# GD32H71x_72x register map
File version: 1.0
CPU: CM7 r1p2, little endian, MPU, FPU, 4 interrupt priority bits
Registers are 32-bit, read-write, reset 0x0 unless marked. A register's access mark holds for its fields unless they carry their own. Offsets are from the block's base; [hi:lo] are bit positions; {n}, {i} and the like mark numbered series.

## RCU — Reset and clock unit
Base 0x58024400
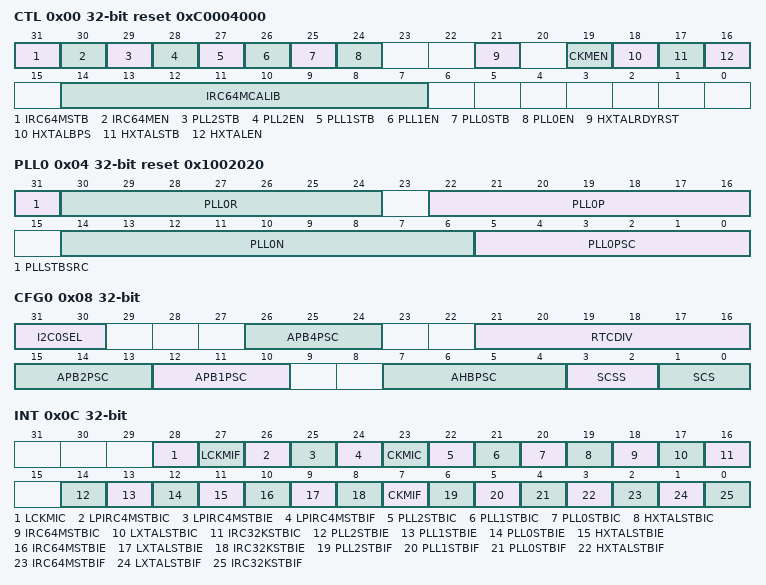
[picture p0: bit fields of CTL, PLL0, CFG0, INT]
0x00 CTL access per field reset 0xC0004000 — Control register
  [31] IRC64MSTB ro — Internal 64MHz RC oscillator stabilization flag
  [30] IRC64MEN rw — Internal 64MHz RC oscillator enable
  [29] PLL2STB ro — PLL2 clock stabilization flag
  [28] PLL2EN rw — PLL2 enable
  [27] PLL1STB ro — PLL1 clock stabilization flag
  [26] PLL1EN rw — PLL1 enable
  [25] PLL0STB ro — PLL0 clock ready flag
  [24] PLL0EN rw — PLL0 enable
  [21] HXTALRDYRST rw — HXTAL ready reset
  [19] CKMEN rw — HXTAL clock monitor enable
  [18] HXTALBPS rw — High-speed crystal oscillator (HXTAL) clock bypass mode enable
  [17] HXTALSTB ro — High-speed crystal oscillator (HXTAL) clock stability flag bit
  [16] HXTALEN rw — High-speed crystal oscillator (HXTAL) enable
  [14:7] IRC64MCALIB ro — Internal 64 MHz RC oscillator calibration value
0x04 PLL0 access per field reset 0x1002020
  [31] PLLSTBSRC wo — PLLs stabilization signal sources.
  [30:24] PLL0R rw — Division factor of the PLL0R output frequency (PLL0 VCO clock as input)
  [22:16] PLL0P rw — PLL0P output frequency division factor (PLL0 VCO clock as input)
  [14:6] PLL0N rw — PLL0 VCO clock multiplication factor
  [5:0] PLL0PSC rw — PLL0 VCO source clock divider
0x08 CFG0 access per field — Clock configuration register 0
  [31:30] I2C0SEL rw — I2C0 clock source selection
  [26:24] APB4PSC rw — APB4 prescaler selection
  [21:16] RTCDIV rw — RTC clock prescaler factor
  [15:13] APB2PSC rw — APB2 prescaler selection
  [12:10] APB1PSC rw — APB1 prescaler selection
  [7:4] AHBPSC rw — AHB / AXI prescaler selection
  [3:2] SCSS ro — System clock selection status
  [1:0] SCS rw — System clock selection
0x0C INT access per field — Clock interrupt register
  [28] LCKMIC wo — LXTAL clock stuck interrupt clear
  [27] LCKMIF ro — LXTAL clock stuck interrupt flag
  [26] LPIRC4MSTBIC wo — LPIRC4M clock stabilization interrupt clear
  [25] LPIRC4MSTBIE rw — LPIRC4M clock stabilization interrupt enable
  [24] LPIRC4MSTBIF ro — LPIRC4M clock stable interrupt flag bit
  [23] CKMIC wo — HXTAL clock stuck interrupt cleared.
  [22] PLL2STBIC wo — PLL2 stabilization interrupt clear
  [21] PLL1STBIC wo — PLL1 stabilization interrupt clear
  [20] PLL0STBIC wo — PLL0 stabilization interrupt clear
  [19] HXTALSTBIC wo — HXTAL stabilization interrupt clear
  [18] IRC64MSTBIC wo — IRC64M stabilization interrupt clear
  [17] LXTALSTBIC wo — LXTAL stabilization interrupt clear
  [16] IRC32KSTBIC wo — IRC32K stabilization interrupt clear
  [14] PLL2STBIE rw — PLL2 stabilization interrupt enable
  [13] PLL1STBIE rw — PLL1 stabilization interrupt enable
  [12] PLL0STBIE rw — PLL0 stabilization interrupt enable
  [11] HXTALSTBIE rw — HXTAL stabilization interrupt enable
  [10] IRC64MSTBIE rw — IRC64M stabilization interrupt enable
  [9] LXTALSTBIE rw — LXTAL stabilization interrupt enable
  [8] IRC32KSTBIE rw — IRC32K stabilization interrupt enable
  [7] CKMIF ro — HXTAL clock stuck interrupt flag bit
  [6] PLL2STBIF ro — PLL2 stabilization interrupt flag
  [5] PLL1STBIF ro — PLL1 stabilization interrupt flag
  [4] PLL0STBIF ro — PLL0 stabilization interrupt flag
  [3] HXTALSTBIF ro — HXTAL stabilization interrupt flag
  [2] IRC64MSTBIF ro — IRC64M stabilization interrupt flag
  [1] LXTALSTBIF ro — LXTAL stabilization interrupt flag
  [0] IRC32KSTBIF ro — IRC32K stabilization interrupt flag
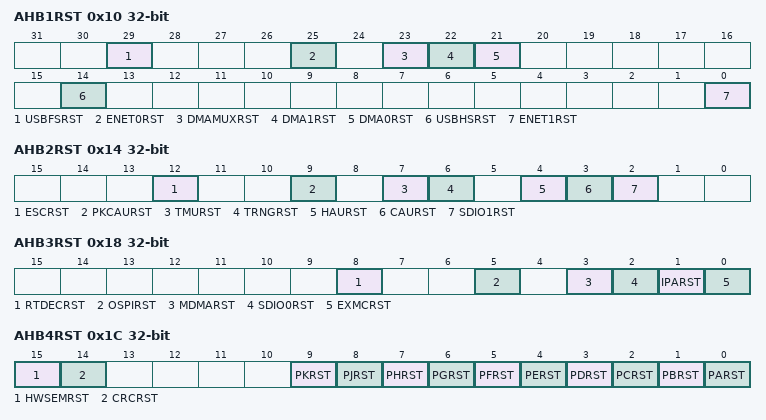
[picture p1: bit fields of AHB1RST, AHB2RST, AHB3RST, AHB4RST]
0x10 AHB1RST — AHB1 reset register
  [29] USBFSRST — USBFS reset
  [25] ENET0RST — Ethernet0 reset
  [23] DMAMUXRST — DMAMUX reset
  [22] DMA1RST — DMA1 reset
  [21] DMA0RST — DMA0 reset
  [14] USBHSRST — USBHS reset
  [0] ENET1RST — Ethernet1 reset
0x14 AHB2RST — AHB2 reset register
  [12] ESCRST — ESC reset
  [9] PKCAURST — PKCAU reset
  [7] TMURST — TMU reset
  [6] TRNGRST — TRNG reset
  [4] HAURST — HAU reset
  [3] CAURST — CAU reset
  [2] SDIO1RST — SDIO1 reset
0x18 AHB3RST — AHB3 reset register
  [8] RTDECRST — RTDEC reset
  [5] OSPIRST — OSPI reset
  [3] MDMARST — MDMA reset
  [2] SDIO0RST — SDIO0 reset
  [1] IPARST — IPA reset
  [0] EXMCRST — EXMC reset
0x1C AHB4RST — AHB4 reset register
  [15] HWSEMRST — HWSEM reset
  [14] CRCRST — CRC reset
  [9] PKRST — GPIO port K reset
  [8] PJRST — GPIO port J reset
  [7] PHRST — GPIO port H reset
  [6] PGRST — GPIO port G reset
  [5] PFRST — Reset GPIO port F
  [4] PERST — Reset GPIO port E
  [3] PDRST — Reset GPIO port D
  [2] PCRST — Reset GPIO port C
  [1] PBRST — Reset GPIO Port B
  [0] PARST — Reset GPIO Port A
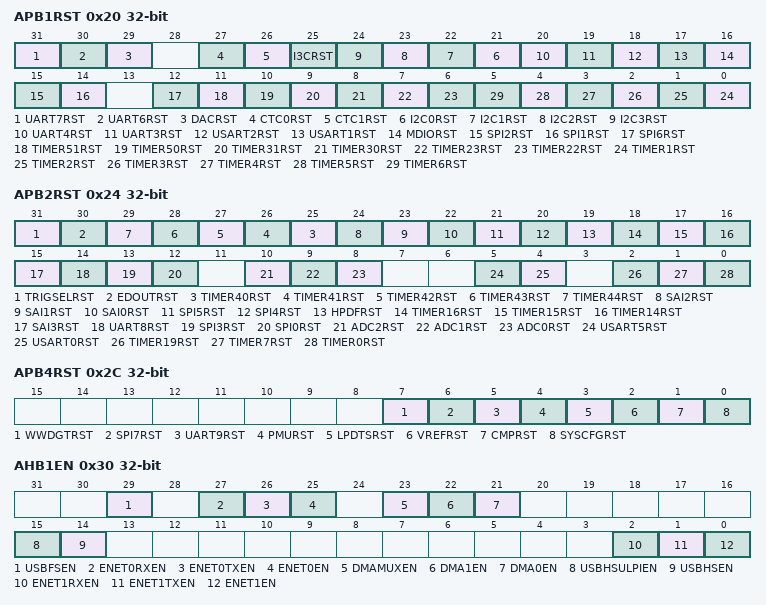
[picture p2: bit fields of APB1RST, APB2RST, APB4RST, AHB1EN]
0x20 APB1RST — APB1 reset register
  [31] UART7RST — UART7 reset
  [30] UART6RST — UART6 reset
  [29] DACRST — DAC reset
  [27] CTC0RST — CTC0 reset
  [26] CTC1RST — CTC1 reset
  [25] I3CRST — I3C reset
  [n+21] I2C{n}RST (n=0..3) — I2C{n} reset
  [20] UART4RST — UART4 reset
  [19] UART3RST — UART3 reset
  [18] USART2RST — USART2 reset
  [17] USART1RST — USART1 reset
  [16] MDIORST — MDIO reset
  [15] SPI2RST — SPI2 reset
  [14] SPI1RST — SPI1 reset
  [12] SPI6RST — SPI6 reset
  [11] TIMER51RST — TIMER51 reset
  [10] TIMER50RST — TIMER50 reset
  [9] TIMER31RST — TIMER31 reset
  [8] TIMER30RST — TIMER30 reset
  [7] TIMER23RST — TIMER23 reset
  [6] TIMER22RST — TIMER22 reset
  [n-1] TIMER{n}RST (n=1..6) — TIMER{n} reset
0x24 APB2RST — APB2 reset register
  [31] TRIGSELRST — TRIGSEL reset
  [30] EDOUTRST — EDOUT reset
  [n-15] TIMER{n}RST (n=40..44) — TIMER{n} reset
  [24] SAI2RST — SAI2 reset
  [23] SAI1RST — SAI1 reset
  [22] SAI0RST — SAI0 reset
  [21] SPI5RST — SPI5 reset
  [20] SPI4RST — SPI4 reset
  [19] HPDFRST — HPDF reset
  [18] TIMER16RST — TIMER16 reset
  [17] TIMER15RST — TIMER15 reset
  [16] TIMER14RST — TIMER14 reset
  [15] SAI3RST — SAI3 reset
  [14] UART8RST — UART8 reset
  [13] SPI3RST — SPI3 reset
  [12] SPI0RST — SPI0 reset
  [10] ADC2RST — ADC2 reset
  [9] ADC1RST — ADC1 reset
  [8] ADC0RST — ADC0 reset
  [5] USART5RST — USART5 reset
  [4] USART0RST — USART0 reset
  [2] TIMER19RST — TIMER19 reset
  [1] TIMER7RST — TIMER7 reset
  [0] TIMER0RST — TIMER0 reset
0x2C APB4RST — APB4 reset register
  [7] WWDGTRST — WWDGT reset
  [6] SPI7RST — SPI7 reset
  [5] UART9RST — UART9 reset
  [4] PMURST — PMU reset
  [3] LPDTSRST — LPDTS reset
  [2] VREFRST — VREF reset
  [1] CMPRST — CMP reset
  [0] SYSCFGRST — SYSCFG reset
0x30 AHB1EN — AHB1 enable register
  [29] USBFSEN — USBFS clock enable
  [27] ENET0RXEN — Ethernet0 RX clock enable
  [26] ENET0TXEN — Ethernet0 TX clock enable
  [25] ENET0EN — Ethernet0 clock enable
  [23] DMAMUXEN — DMAMUX clock enable
  [22] DMA1EN — DMA1 clock enable
  [21] DMA0EN — DMA0 clock enable
  [15] USBHSULPIEN — USBHS ULPI clock enable
  [14] USBHSEN — USBHS clock enable
  [2] ENET1RXEN — Ethernet1 RX clock enable
  [1] ENET1TXEN — Ethernet1 TX clock enable
  [0] ENET1EN — Ethernet1 clock enable
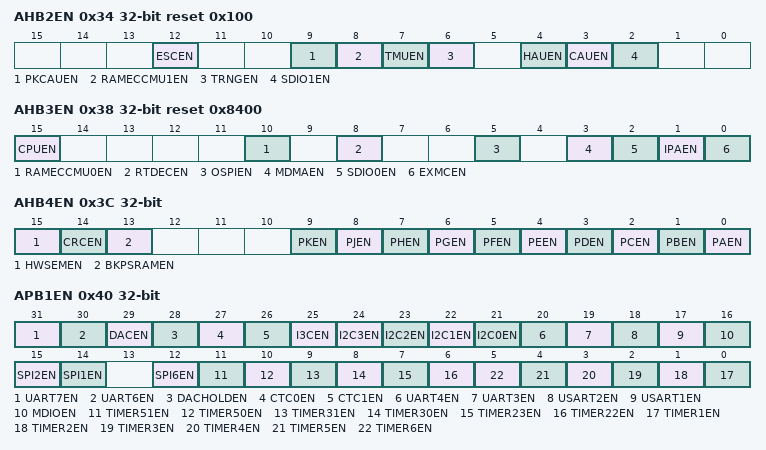
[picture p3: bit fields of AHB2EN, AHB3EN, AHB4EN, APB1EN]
0x34 AHB2EN reset 0x100 — AHB2 enable register
  [12] ESCEN — ESC clock enable
  [9] PKCAUEN — PKCAU clock enable
  [8] RAMECCMU1EN — Enable RAMECCMU1 clock
  [7] TMUEN — Enable TMU clock
  [6] TRNGEN — Enable TRNG clock
  [4] HAUEN — HAU clock enable
  [3] CAUEN — CAU clock enable
  [2] SDIO1EN — SDIO1 clock enable
0x38 AHB3EN reset 0x8400 — AHB3 enable register
  [15] CPUEN — CPU clock enable
  [10] RAMECCMU0EN — RAMECCMU0 clock enable
  [8] RTDECEN — RTDEC clock enable
  [5] OSPIEN — OSPI clock enable
  [3] MDMAEN — MDMA clock enable
  [2] SDIO0EN — SDIO0 clock enable
  [1] IPAEN — IPA clock enable
  [0] EXMCEN — Enable EXMC clock
0x3C AHB4EN — AHB4 enable register
  [15] HWSEMEN — Enable HWSEM clock
  [14] CRCEN — Enable CRC clock
  [13] BKPSRAMEN — Enable BKPSRAM clock
  [9] PKEN — Enable GPIO Port K clock.
  [8] PJEN — Enable GPIO Port J clock.
  [7] PHEN — Enable GPIO Port H clock.
  [6] PGEN — Enable GPIO port G clock
  [5] PFEN — Enable GPIO port F clock
  [4] PEEN — Enable GPIO port E clock
  [3] PDEN — Enable GPIO port D clock
  [2] PCEN — Enable GPIO port C clock
  [1] PBEN — Enable GPIO port B clock
  [0] PAEN — Enable GPIO port A clock
0x40 APB1EN — APB1 enable register
  [31] UART7EN — Enable UART7 clock
  [30] UART6EN — UART6 clock enable
  [29] DACEN — DAC clock enable
  [28] DACHOLDEN — DAC hold clock enable
  [27] CTC0EN — CTC0 clock enable
  [26] CTC1EN — CTC1 clock enable
  [25] I3CEN — I3C clock enable
  [n+21] I2C{n}EN (n=0..3) — I2C{n} clock enable
  [20] UART4EN — UART4 clock enable
  [19] UART3EN — UART3 clock enable
  [18] USART2EN — USART2 clock enable
  [17] USART1EN — USART1 clock enable
  [16] MDIOEN — MDIO clock enable
  [15] SPI2EN — SPI2 clock enable
  [14] SPI1EN — SPI1 clock enable
  [12] SPI6EN — SPI6 clock enable
  [11] TIMER51EN — TIMER51 clock enable
  [10] TIMER50EN — TIMER50 clock enable
  [9] TIMER31EN — TIMER31 clock enable
  [8] TIMER30EN — TIMER30 clock enable
  [7] TIMER23EN — TIMER23 clock enable
  [6] TIMER22EN — TIMER22 clock enable
  [n-1] TIMER{n}EN (n=1..6) — TIMER{n} clock enable
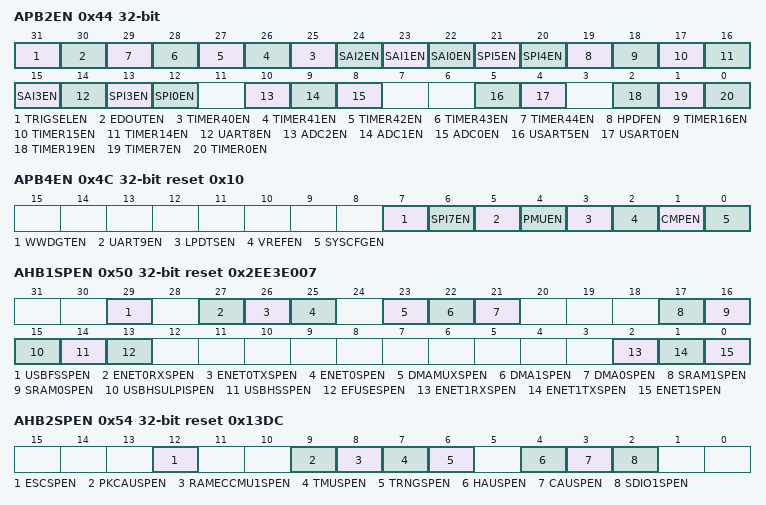
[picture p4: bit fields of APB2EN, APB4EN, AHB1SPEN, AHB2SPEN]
0x44 APB2EN — APB2 enable register
  [31] TRIGSELEN — TRIGSEL clock enable
  [30] EDOUTEN — EDOUT clock enable
  [n-15] TIMER{n}EN (n=40..44) — TIMER{n} clock enable
  [24] SAI2EN — SAI2 clock enable
  [23] SAI1EN — SAI1 clock enable
  [22] SAI0EN — SAI0 clock enable
  [21] SPI5EN — SPI5 clock enable
  [20] SPI4EN — SPI4 clock enable
  [19] HPDFEN — HPDF clock enable
  [18] TIMER16EN — TIMER16 clock enable
  [17] TIMER15EN — TIMER15 clock enable
  [16] TIMER14EN — TIMER14 clock enable
  [15] SAI3EN — SAI3 clock enable
  [14] UART8EN — UART8 clock enable
  [13] SPI3EN — SPI3 clock enable
  [12] SPI0EN — SPI0 clock enable
  [10] ADC2EN — ADC2 clock enable
  [9] ADC1EN — ADC1 clock enable
  [8] ADC0EN — ADC0 clock enable
  [5] USART5EN — USART5 clock enable
  [4] USART0EN — USART0 clock enable
  [2] TIMER19EN — TIMER19 clock enable
  [1] TIMER7EN — TIMER7 clock enable
  [0] TIMER0EN — TIMER0 clock enable
0x4C APB4EN reset 0x10 — APB4 enable register
  [7] WWDGTEN — WWDGTEN clock enable
  [6] SPI7EN — SPI7EN clock enable
  [5] UART9EN — UART9EN clock enable
  [4] PMUEN — PMU clock enable
  [3] LPDTSEN — LPDTS clock enable
  [2] VREFEN — VREF clock enable
  [1] CMPEN — CMP clock enable
  [0] SYSCFGEN — SYSCFG clock enable
0x50 AHB1SPEN reset 0x2EE3E007 — AHB1 sleep mode enable register
  [29] USBFSSPEN — Enable USBFS clock in sleep mode.
  [27] ENET0RXSPEN — Enable Ethernet0 RX clock in sleep mode.
  [26] ENET0TXSPEN — Enable Ethernet0 TX clock in sleep mode.
  [25] ENET0SPEN — Enable Ethernet0 clock in sleep mode
  [23] DMAMUXSPEN — Enable DMAMUX clock in sleep mode
  [22] DMA1SPEN — Enable DMA1 clock in sleep mode.
  [21] DMA0SPEN — Enable DMA0 clock in sleep mode.
  [17] SRAM1SPEN — Enable SRAM1 clock in sleep mode.
  [16] SRAM0SPEN — Enable SRAM0 clock in sleep mode.
  [15] USBHSULPISPEN — Enable USBHS ULPI clock in sleep mode.
  [14] USBHSSPEN — Enable USBHS clock in sleep mode
  [13] EFUSESPEN — Enable EFUSE clock in sleep mode
  [2] ENET1RXSPEN — Enable Ethernet1 RX clock in sleep mode
  [1] ENET1TXSPEN — Enable Ethernet1 TX clock in sleep mode
  [0] ENET1SPEN — Enable Ethernet1 clock in sleep mode
0x54 AHB2SPEN reset 0x13DC — AHB2 sleep mode enable register
  [12] ESCSPEN — Enable ESC clock in sleep mode
  [9] PKCAUSPEN — Enable PKCAU clock in sleep mode
  [8] RAMECCMU1SPEN — Enable RAMECCMU1 clock in sleep mode
  [7] TMUSPEN — Enable TMU clock in sleep mode
  [6] TRNGSPEN — Enable TRNG clock in sleep mode
  [4] HAUSPEN — Enable HAU clock in sleep mode
  [3] CAUSPEN — Enable CAU clock in sleep mode
  [2] SDIO1SPEN — Enable SDIO1 clock in sleep mode
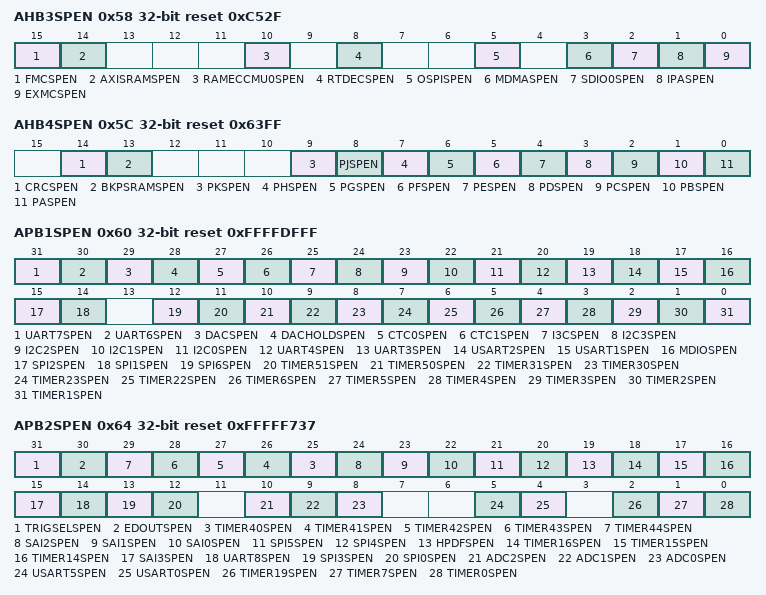
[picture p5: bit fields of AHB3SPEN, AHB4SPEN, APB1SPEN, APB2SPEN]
0x58 AHB3SPEN reset 0xC52F — AHB3 sleep mode enable register
  [15] FMCSPEN — Enable FMC clock in sleep mode
  [14] AXISRAMSPEN — Enable AXI SRAM clock in sleep mode
  [10] RAMECCMU0SPEN — Enable RAMECCMU0 clock in sleep mode
  [8] RTDECSPEN — Enable RTDEC clock in sleep mode
  [5] OSPISPEN — Enable OSPI clock in sleep mode.
  [3] MDMASPEN — Enable MDMA clock in sleep mode.
  [2] SDIO0SPEN — Enable SDIO0 clock in sleep mode.
  [1] IPASPEN — Enable IPA clock in sleep mode
  [0] EXMCSPEN — Enable EXMC clock in sleep mode
0x5C AHB4SPEN reset 0x63FF — AHB4 sleep mode enable register
  [14] CRCSPEN — Enable CRC clock in sleep mode
  [13] BKPSRAMSPEN — Enable Backup domain SRAM clock in sleep mode
  [9] PKSPEN — Enable GPIO port K clock in sleep mode.
  [8] PJSPEN — Enable GPIO port J clock in sleep mode.
  [7] PHSPEN — Enable GPIO port H clock in sleep mode.
  [6] PGSPEN — Enable GPIO port G clock in sleep mode
  [5] PFSPEN — Enable GPIO port F clock in sleep mode
  [4] PESPEN — Enable GPIO port E clock in sleep mode
  [3] PDSPEN — Enable GPIO port D clock in sleep mode
  [2] PCSPEN — Enable the GPIO port C clock in sleep mode
  [1] PBSPEN — Enable the GPIO port B clock in sleep mode
  [0] PASPEN — Enable the GPIO port A clock in sleep mode
0x60 APB1SPEN reset 0xFFFFDFFF — APB1 sleep mode enable register
  [31] UART7SPEN — Enable the UART7 clock in sleep mode
  [30] UART6SPEN — UART6 clock enabled in sleep mode
  [29] DACSPEN — DAC clock enabled in sleep mode
  [28] DACHOLDSPEN — DAC hold clock enabled in sleep mode
  [27] CTC0SPEN — CTC0 remains clock enable in sleep mode
  [26] CTC1SPEN — CTC1 clock enable in sleep mode
  [25] I3CSPEN — I3C clock enable in sleep mode
  [24] I2C3SPEN — I2C3 clock enable in sleep mode
  [23] I2C2SPEN — Enable I2C2 clock in sleep mode
  [22] I2C1SPEN — Enable I2C1 clock in sleep mode
  [21] I2C0SPEN — Enable I2C0 clock in sleep mode
  [20] UART4SPEN — Enable UART4 clock in sleep mode
  [19] UART3SPEN — Enable UART3 clock in sleep mode
  [18] USART2SPEN — Enable USART2 clock in sleep mode
  [17] USART1SPEN — Enable USART1 clock in sleep mode
  [16] MDIOSPEN — Enable MDIO clock in sleep mode
  [15] SPI2SPEN — Enable SPI2 clock in sleep mode
  [14] SPI1SPEN — Enable SPI1 clock in sleep mode
  [12] SPI6SPEN — Enable SPI6 clock in sleep mode
  [11] TIMER51SPEN — Enable TIMER51 clock in sleep mode
  [10] TIMER50SPEN — Enable TIMER50 clock in sleep mode
  [9] TIMER31SPEN — Enable TIMER31 clock in sleep mode
  [8] TIMER30SPEN — Enable TIMER30 clock in sleep mode
  [7] TIMER23SPEN — Enable the TIMER23 clock in sleep mode
  [6] TIMER22SPEN — Enable the TIMER22 clock in sleep mode
  [5] TIMER6SPEN — Enable the TIMER6 clock in sleep mode
  [4] TIMER5SPEN — Enable the TIMER5 clock in sleep mode
  [3] TIMER4SPEN — TIMER4 clock enabled in sleep mode
  [2] TIMER3SPEN — TIMER3 clock enabled in sleep mode
  [1] TIMER2SPEN — TIMER2 clock enabled in sleep mode
  [0] TIMER1SPEN — Enable TIMER1 clock in sleep mode
0x64 APB2SPEN reset 0xFFFFF737 — APB2 sleep mode enable register
  [31] TRIGSELSPEN — Enable TRIGSEL clock in sleep mode
  [30] EDOUTSPEN — Enable EDOUT clock in sleep mode
  [n-15] TIMER{n}SPEN (n=40..44) — Enable TIMER{n} clock in sleep mode
  [24] SAI2SPEN — Enable SAI2 clock in sleep mode
  [23] SAI1SPEN — Enable SAI1 clock in sleep mode
  [22] SAI0SPEN — Enable SAI0 clock in sleep mode
  [21] SPI5SPEN — Enable SPI5 clock in sleep mode
  [20] SPI4SPEN — Enable SPI4 clock in sleep mode
  [19] HPDFSPEN — Enable HPDF clock in sleep mode
  [18] TIMER16SPEN — Enable TIMER16 clock in sleep mode
  [17] TIMER15SPEN — Enable TIMER15 clock in sleep mode
  [16] TIMER14SPEN — Enable TIMER14 clock in sleep mode
  [15] SAI3SPEN — Enable SAI3 clock in sleep mode
  [14] UART8SPEN — Enable UART8 clock in sleep mode
  [13] SPI3SPEN — Enable SPI3 clock in sleep mode
  [12] SPI0SPEN — Enable SPI0 clock in sleep mode
  [10] ADC2SPEN — Enable ADC2 clock in sleep mode
  [9] ADC1SPEN — Enable ADC1 clock in sleep mode
  [8] ADC0SPEN — ADC0 clock enabled in sleep mode
  [5] USART5SPEN — USART5 clock enabled in sleep mode
  [4] USART0SPEN — USART0 clock enabled in sleep mode
  [2] TIMER19SPEN — Enable the TIMER19 clock in sleep mode.
  [1] TIMER7SPEN — Enable the TIMER7 clock in sleep mode.
  [0] TIMER0SPEN — Enable the TIMER0 clock in sleep mode.
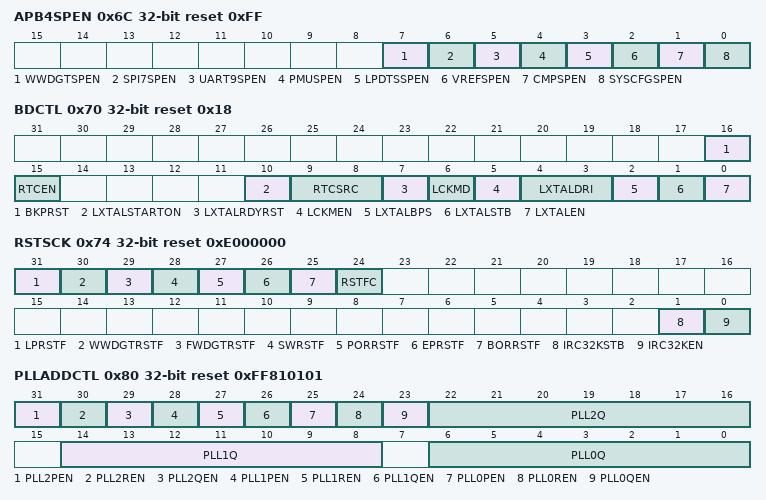
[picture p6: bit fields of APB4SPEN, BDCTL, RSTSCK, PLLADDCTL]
0x6C APB4SPEN reset 0xFF — APB4 sleep mode enable register
  [7] WWDGTSPEN — Enable WWDGT clock in sleep mode
  [6] SPI7SPEN — Enable SPI7 clock in sleep mode
  [5] UART9SPEN — Enable UART9 clock in sleep mode
  [4] PMUSPEN — Enable PMU clock in sleep mode
  [3] LPDTSSPEN — Enable LPDTS clock in sleep mode
  [2] VREFSPEN — Enable VREF clock in sleep mode
  [1] CMPSPEN — Enable CMP clock in sleep mode
  [0] SYSCFGSPEN — Enable SYSCFG clock in sleep mode
0x70 BDCTL access per field reset 0x18 — Backup domain control register
  [16] BKPRST rw — Backup domain reset.
  [15] RTCEN rw — RTC clock enable.
  [10] LXTALSTARTON rw — LXTAL start circuit on control
  [9:8] RTCSRC rw — RTC clock source selection
  [7] LXTALRDYRST rw — LXTAL ready reset
  [6] LCKMD ro — LXTAL clock failure detection
  [5] LCKMEN rw — LXTAL clock monitor enable
  [4:3] LXTALDRI rw — LXTAL driving capability
  [2] LXTALBPS rw — LXTAL bypass mode enable
  [1] LXTALSTB ro — Low-speed crystal oscillator stability flag
  [0] LXTALEN rw — LXTAL clock enable
0x74 RSTSCK access per field reset 0xE000000 — Reset source/clock register
  [31] LPRSTF ro — Low-power reset flag
  [30] WWDGTRSTF ro — Window watchdog timer reset flag
  [29] FWDGTRSTF ro — Free watchdog timer reset flag bit
  [28] SWRSTF ro — Software reset flag bit
  [27] PORRSTF ro — Power reset flag bit
  [26] EPRSTF ro — External pin reset flag bit
  [25] BORRSTF ro — Under-voltage reset flag bit
  [24] RSTFC rw — Clear reset flag bit
  [1] IRC32KSTB ro — IRC32K clock stable flag
  [0] IRC32KEN rw — IRC32Kenable
0x80 PLLADDCTL reset 0xFF810101 — PLL clock additional control register
  [31] PLL2PEN — PLL2P divider output enable
  [30] PLL2REN — PLL2R divider output enable
  [29] PLL2QEN — Enable PLL2Q prescaler output
  [28] PLL1PEN — Enable PLL1P prescaler output
  [27] PLL1REN — Enable PLL1R prescaler output
  [26] PLL1QEN — Enable PLL1Q prescaler output
  [25] PLL0PEN — PLL0P divider output enable
  [24] PLL0REN — PLL0R divider output enable
  [23] PLL0QEN — PLL0Q divider output enable
  [22:16] PLL2Q — Division factor for the PLL2Q output frequency (PLL2 VCO clock as input)
  [14:8] PLL1Q — Division factor for the PLL1Q output frequency (PLL1 VCO clock as input)
  [6:0] PLL0Q — The division factor of the PLL0Q output frequency (PLL0 VCO clock as input).
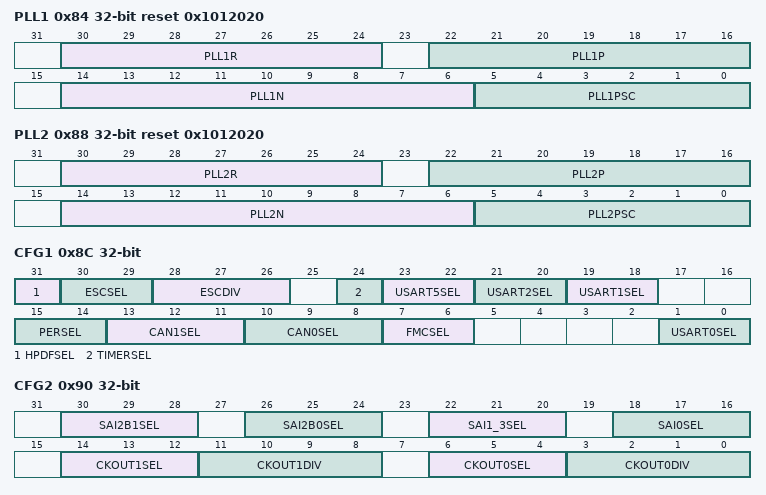
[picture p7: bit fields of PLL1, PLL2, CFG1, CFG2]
0x84 PLL1 reset 0x1012020
  [30:24] PLL1R — The division factor of the PLL1R output frequency (PLL1 VCO clock as input).
  [22:16] PLL1P — The division factor of the PLL1P output frequency (PLL1 VCO clock as input).
  [14:6] PLL1N — PLL1 VCO clock multiplication factor
  [5:0] PLL1PSC — PLL1 VCO source clock divider
0x88 PLL2 reset 0x1012020
  [30:24] PLL2R — Division factor of the PLL2R output frequency (PLL2 VCO clock as input).
  [22:16] PLL2P — Division factor of the PLL2P output frequency (PLL2 VCO clock as input).
  [14:6] PLL2N — PLL2 VCO clock multiplication factor
  [5:0] PLL2PSC — PLL2 VCO source clock divider
0x8C CFG1 — Clock configuration register 1
  [31] HPDFSEL — HPDF clock source selection
  [30:29] ESCSEL — ESC clock source selection
  [28:26] ESCDIV — ESC clock division factor
  [24] TIMERSEL — TIMER clock selection
  [23:22] USART5SEL — USART5 clock source selection.
  [21:20] USART2SEL — USART2 clock source selection
  [19:18] USART1SEL — USART1 clock source selection
  [15:14] PERSEL — CK_PER clock source selection
  [13:11] CAN1SEL — CAN1 clock source selection
  [10:8] CAN0SEL — CAN0 clock source selection
  [7:6] FMCSEL — FMC clock source selection
  [1:0] USART0SEL — USART0 clock source selection
0x90 CFG2 — Clock configuration register 2
  [30:28] SAI2B1SEL — SAI2 Block 1 clock source selection
  [26:24] SAI2B0SEL — SAI2 Block 0 Clock Source Selection
  [22:20] SAI1_3SEL — SAI1 and SAI3 Clock Source Selection
  [18:16] SAI0SEL — SAI0 / HPDF audio clock source selection
  [14:12] CKOUT1SEL — CKOUT1 clock source selection
  [11:8] CKOUT1DIV — CK_OUT1 divider, to reduce CK_OUT1 frequency
  [6:4] CKOUT0SEL — CKOUT0 clock source selection
  [3:0] CKOUT0DIV — CK_OUT0 divider, used to reduce CK_OUT0 frequency.
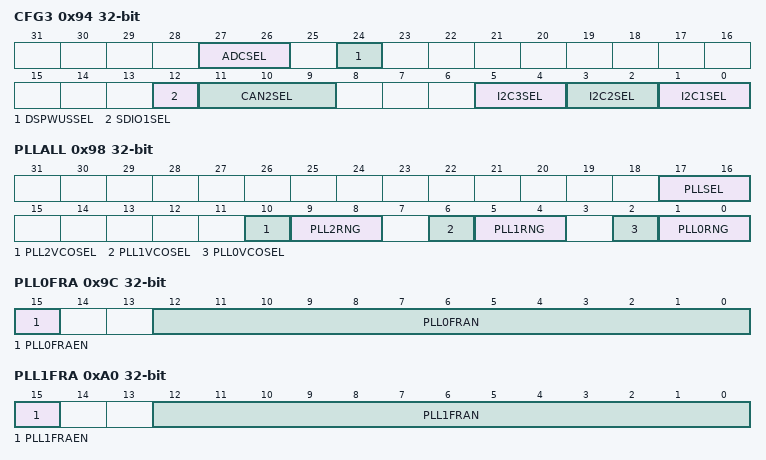
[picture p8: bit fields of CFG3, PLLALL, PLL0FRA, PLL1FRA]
0x94 CFG3 — Clock configuration register 3
  [27:26] ADCSEL — ADC0/ADC1/ADC2 clock source selection.
  [24] DSPWUSSEL — Deep-sleep wakeup system clock source selection
  [12] SDIO1SEL — SDIO1 clock source selection.
  [11:9] CAN2SEL — CAN2 clock source selection.
  [5:4] I2C3SEL — I2C3 clock source selection
  [3:2] I2C2SEL — I2C2 clock source selection
  [1:0] I2C1SEL — I2C1 clock source selection
0x98 PLLALL — PLL control register
  [17:16] PLLSEL — PLLs clock source selection
  [10] PLL2VCOSEL — PLL2 VCO range selection
  [9:8] PLL2RNG — PLL2 input clock range
  [6] PLL1VCOSEL — PLL1 VCO range selection
  [5:4] PLL1RNG — PLL1 input clock range
  [2] PLL0VCOSEL — PLL0 VCO range selection
  [1:0] PLL0RNG — PLL0 input clock range
0x9C PLL0FRA — PLL0 fractional configuration register
  [15] PLL0FRAEN — PLL0 fractional latch enable
  [12:0] PLL0FRAN — Fractional part of PLL0 VCO multiplication factor.
0xA0 PLL1FRA — PLL1 fractional configuration register
  [15] PLL1FRAEN — PLL1 fractional latch enable
  [12:0] PLL1FRAN — Fractional part of PLL1 VCO multiplication factor
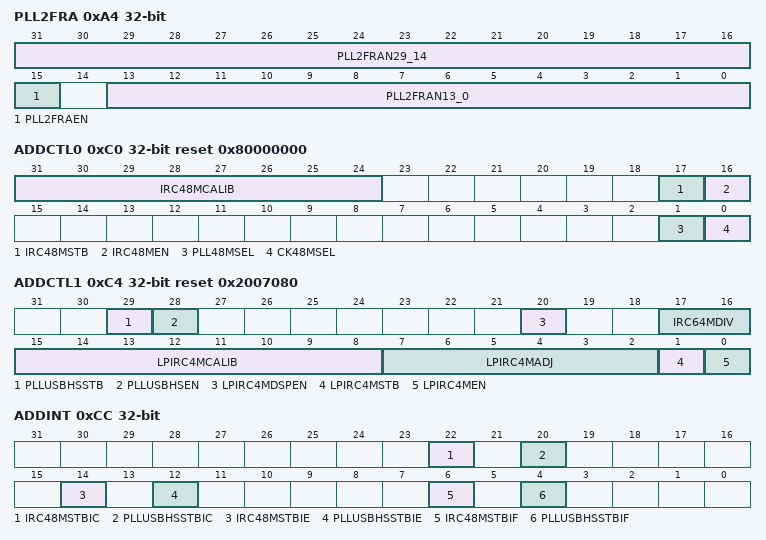
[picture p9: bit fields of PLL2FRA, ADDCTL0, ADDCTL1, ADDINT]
0xA4 PLL2FRA — PLL2 fractional configuration register
  [31:16] PLL2FRAN29_14 — Fractional part of PLL2 VCO multiplication factor
  [15] PLL2FRAEN — PLL2 fractional latch enable
  [13:0] PLL2FRAN13_0 — Fractional part of PLL2 VCO multiplication factor
0xC0 ADDCTL0 access per field reset 0x80000000 — Additional clock control register 0
  [31:24] IRC48MCALIB ro — Internal 48MHz RC oscillator calibration value register
  [17] IRC48MSTB ro — Internal 48MHz RC oscillator clock stability flag bit
  [16] IRC48MEN rw — Internal 48MHz RC oscillator enable
  [1] PLL48MSEL rw — PLL48M clock source selection
  [0] CK48MSEL rw — 48MHz clock source selection
0xC4 ADDCTL1 access per field reset 0x2007080 — Additional clock control register 1
  [29] PLLUSBHSSTB ro — PLLUSBHS clock ready flag bit
  [28] PLLUSBHSEN rw — PLLUSBHS clock enable
  [20] LPIRC4MDSPEN rw — Enable the LPIRC4M clock in Deep Sleep mode.
  [17:16] IRC64MDIV rw — IRC64M clock division
  [15:8] LPIRC4MCALIB ro — LPIRC4M clock calibration value
  [7:2] LPIRC4MADJ rw — LPIRC4M clock trimming value
  [1] LPIRC4MSTB ro — LPIRC4M clock stable flag bit
  [0] LPIRC4MEN rw — LPIRC4M RC oscillator enable
0xCC ADDINT access per field — Additional clock interrupt register
  [22] IRC48MSTBIC wo — Internal 48 MHz RC oscillator stable interrupt clear.
  [20] PLLUSBHSSTBIC wo — USBHS internal PLL clock stable interrupt clear.
  [14] IRC48MSTBIE rw — Internal 48 MHz RC oscillator stabilization interrupt enable.
  [12] PLLUSBHSSTBIE rw — USBHS internal PLL clock stabilization interrupt enable.
  [6] IRC48MSTBIF ro — IRC48M clock stabilization interrupt flag bit.
  [4] PLLUSBHSSTBIF ro — USBHS internal PLL clock stability interrupt flag bit.
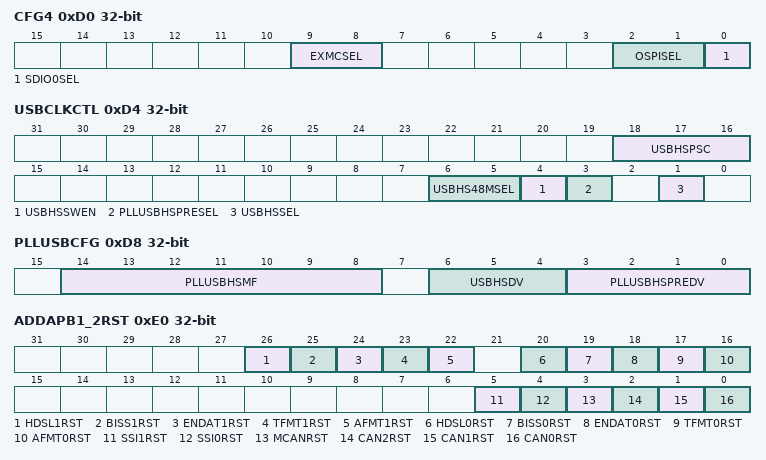
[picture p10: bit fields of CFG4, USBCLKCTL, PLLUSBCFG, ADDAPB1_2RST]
0xD0 CFG4 — Clock configuration register 4
  [9:8] EXMCSEL — EXMC clock source selection.
  [2:1] OSPISEL — OSPI clock source selection
  [0] SDIO0SEL — SDIO0 clock source selection
0xD4 USBCLKCTL — USB clock control register
  [18:16] USBHSPSC — Clock division factor of USBHS
  [6:5] USBHS48MSEL — USBHS 48M clock source selection
  [4] USBHSSWEN — Enable USBHS clock source selection
  [3] PLLUSBHSPRESEL — PLLUSBHS pre-clock source selection
  [1] USBHSSEL — USBHS clock source selection
0xD8 PLLUSBCFG — PLLUSB clock configuration register
  [14:8] PLLUSBHSMF — PLLUSBHS clock multiplication factor
  [6:4] USBHSDV — USBHS clock division factor
  [3:0] PLLUSBHSPREDV — Clock division factor of PLLUSBHSPREDV
0xE0 ADDAPB1_2RST — APB additional reset register
  [26] HDSL1RST — HDSL1 reset
  [25] BISS1RST — BISS1 reset
  [24] ENDAT1RST — ENDAT1 reset
  [23] TFMT1RST — TFMT1 reset
  [22] AFMT1RST — AFMT1 reset
  [20] HDSL0RST — HDSL0 reset
  [19] BISS0RST — BISS0 reset
  [18] ENDAT0RST — ENDAT0 reset
  [17] TFMT0RST — TFMT0 reset
  [16] AFMT0RST — AFMT0 reset
  [5] SSI1RST — SSI1 reset
  [4] SSI0RST — SSI0 reset
  [3] MCANRST — MCAN reset
  [2] CAN2RST — CAN2 reset
  [1] CAN1RST — CAN1 reset
  [0] CAN0RST — CAN0 reset
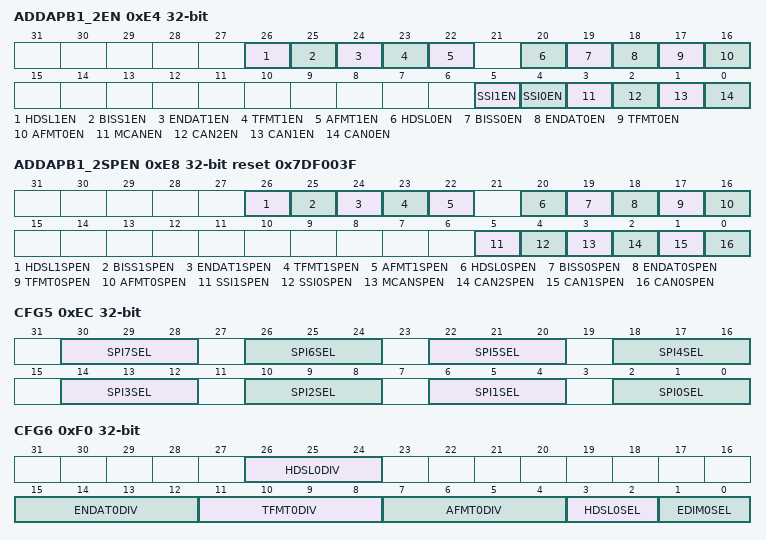
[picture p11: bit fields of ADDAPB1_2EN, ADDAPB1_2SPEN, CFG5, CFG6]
0xE4 ADDAPB1_2EN — APB additional enable register
  [26] HDSL1EN — HDSL1 clock enable
  [25] BISS1EN — BISS1 clock enable
  [24] ENDAT1EN — ENDAT1 clock enable
  [23] TFMT1EN — TFMT1 clock enable
  [22] AFMT1EN — AFMT1 clock enable
  [20] HDSL0EN — HDSL0 clock enable
  [19] BISS0EN — BISS0 clock enable
  [18] ENDAT0EN — ENDAT0 clock enable
  [17] TFMT0EN — TFMT0 clock enable
  [16] AFMT0EN — AFMT0 clock enable
  [5] SSI1EN — SSI1 clock enable
  [4] SSI0EN — SSI0 clock enable
  [3] MCANEN — Enable MCAN clock
  [2] CAN2EN — Enable CAN2 clock
  [1] CAN1EN — Enable CAN1 clock
  [0] CAN0EN — Enable CAN0 clock
0xE8 ADDAPB1_2SPEN reset 0x7DF003F — APB additional sleep mode enable register
  [26] HDSL1SPEN — Enable HDSL1 clock in sleep mode.
  [25] BISS1SPEN — Enable BISS1 clock in sleep mode.
  [24] ENDAT1SPEN — Enable ENDAT1 clock in sleep mode.
  [23] TFMT1SPEN — Enable TFMT1 clock in sleep mode
  [22] AFMT1SPEN — Enable AFMT1 clock in sleep mode
  [20] HDSL0SPEN — Enable HDSL0 clock in sleep mode
  [19] BISS0SPEN — Enable BISS0 clock in sleep mode
  [18] ENDAT0SPEN — Enable ENDAT0 clock in sleep mode
  [17] TFMT0SPEN — Enable TFMT0 clock in sleep mode
  [16] AFMT0SPEN — Enable AFMT0 clock in sleep mode
  [5] SSI1SPEN — Enable SSI1 clock in sleep mode
  [4] SSI0SPEN — Enable SSI0 clock in sleep mode
  [3] MCANSPEN — Enable MCAN clock in sleep mode
  [2] CAN2SPEN — Enable CAN2 clock in sleep mode
  [1] CAN1SPEN — Enable CAN1 clock in sleep mode
  [0] CAN0SPEN — Enable CAN0 clock in sleep mode
0xEC CFG5 — Clock configuration register 5
  [30:28] SPI7SEL — SPI7 clock source selection
  [26:24] SPI6SEL — SPI6 clock source selection
  [22:20] SPI5SEL — SPI5 / I2S5 clock source selection
  [18:16] SPI4SEL — SPI4 clock source selection
  [14:12] SPI3SEL — SPI3 clock source selection
  [10:8] SPI2SEL — SPI2 / I2S2 clock source selection
  [6:4] SPI1SEL — SPI1 / I2S1 clock source selection
  [2:0] SPI0SEL — SPI0/I2S0 clock source selection
0xF0 CFG6 — Clock configuration register 6
  [26:24] HDSL0DIV — HDSL0 division factor
  [15:12] ENDAT0DIV — ENDAT0 prescaler factor
  [11:8] TFMT0DIV — TFMT0 prescaler factor
  [7:4] AFMT0DIV — AFMT0 prescaler factor
  [3:2] HDSL0SEL — HDSL0 clock source selection
  [1:0] EDIM0SEL — EDIM0 clock source selection
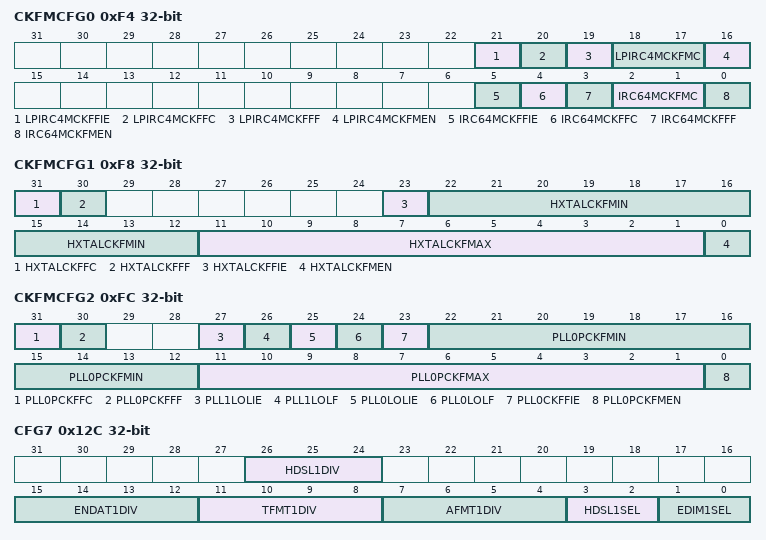
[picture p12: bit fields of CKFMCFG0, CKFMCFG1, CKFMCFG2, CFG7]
0xF4 CKFMCFG0 access per field — Clock frequency monitoring configuration register 0
  [21] LPIRC4MCKFFIE rw — LPIRC4M clock frequency fault interrupt enable
  [20] LPIRC4MCKFFC rw — LPIRC4M clock frequency fault flag clear
  [19] LPIRC4MCKFFF ro — LPIRC4M clock frequency fault flag
  [18:17] LPIRC4MCKFMC rw — LPIRC4M clock frequency monitor configuration
  [16] LPIRC4MCKFMEN rw — LPIRC4M clock frequency monitor enable.
  [5] IRC64MCKFFIE rw — IRC64M clock frequency fault interrupt enable.
  [4] IRC64MCKFFC rw — IRC64M clock frequency fault flag clear.
  [3] IRC64MCKFFF ro — IRC64M clock frequency fault flag
  [2:1] IRC64MCKFMC rw — IRC64M clock frequency monitor configuration
  [0] IRC64MCKFMEN rw — IRC64M clock frequency monitor enable
0xF8 CKFMCFG1 access per field — Clock frequency monitoring configuration register 1
  [31] HXTALCKFFC rw — Clear HXTAL clock frequency fault flag
  [30] HXTALCKFFF ro — HXTAL clock frequency fault flag
  [23] HXTALCKFFIE rw — HXTAL clock frequency fault interrupt enable
  [22:12] HXTALCKFMIN rw — HXTAL clock frequency monitor minimum configuration value
  [11:1] HXTALCKFMAX rw — HXTAL clock frequency monitor maximum configuration value
  [0] HXTALCKFMEN rw — HXTAL clock frequency monitor enable.
0xFC CKFMCFG2 access per field — Clock frequency monitoring configuration register 2
  [31] PLL0PCKFFC rw — PLL0P clock frequency fault flag clear.
  [30] PLL0PCKFFF ro — PLL0P clock frequency fault flag.
  [27] PLL1LOLIE rw — PLL1 lock loss interrupt enable.
  [26] PLL1LOLF rw — PLL1 clock loss flag.
  [25] PLL0LOLIE rw — PLL0 clock loss interrupt enable.
  [24] PLL0LOLF rw — PLL0 clock loss flag.
  [23] PLL0CKFFIE rw — PLL0 clock frequency fault interrupt enable
  [22:12] PLL0PCKFMIN rw — PLL0P clock frequency monitor configuration minimum value
  [11:1] PLL0PCKFMAX rw — PLL0P clock frequency monitor configuration maximum value
  [0] PLL0PCKFMEN rw — PLL0P clock frequency monitor enable
0x12C CFG7 — Clock configuration register 7
  [26:24] HDSL1DIV — HDSL1 division factor
  [15:12] ENDAT1DIV — ENDAT1 prescaler factor
  [11:8] TFMT1DIV — TFMT1 prescaler factor
  [7:4] AFMT1DIV — AFMT1 prescaler factor
  [3:2] HDSL1SEL — HDSL1 clock source selection
  [1:0] EDIM1SEL — EDIM1 clock source selection
